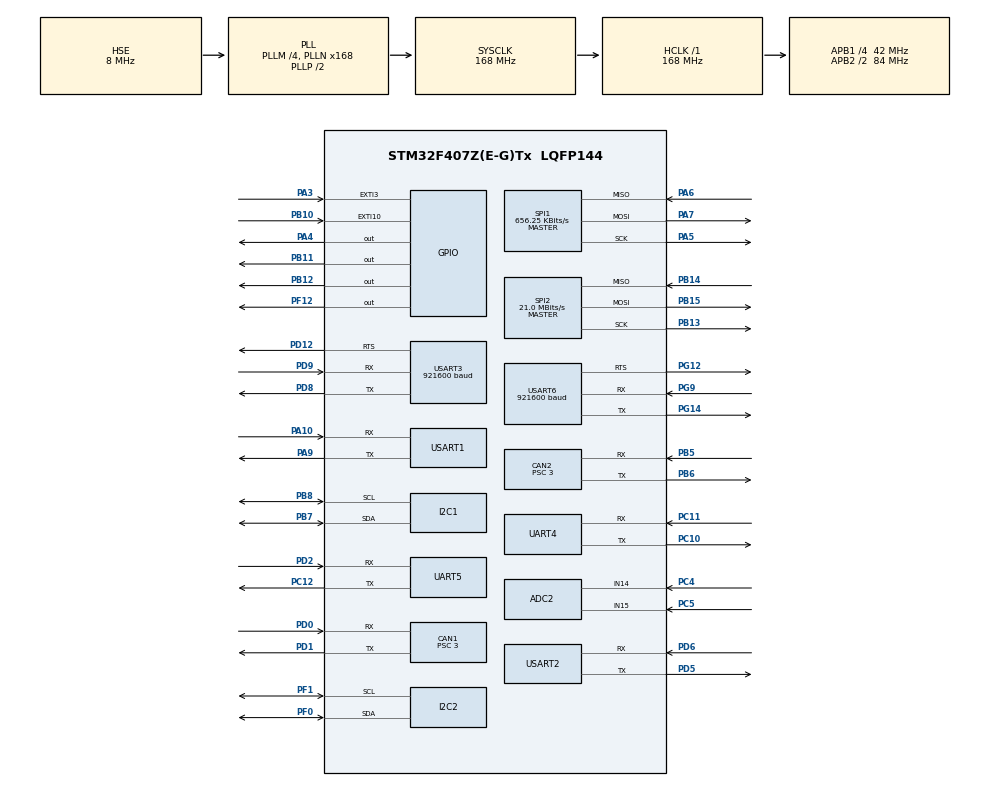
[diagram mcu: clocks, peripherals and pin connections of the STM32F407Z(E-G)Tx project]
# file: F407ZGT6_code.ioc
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ADC2.Channel-3\#ChannelRegularConversion=ADC_CHANNEL_14
ADC2.NbrOfConversionFlag=1
ADC2.Rank-3\#ChannelRegularConversion=1
ADC2.SamplingTime-3\#ChannelRegularConversion=ADC_SAMPLETIME_3CYCLES
CAN1.BS1=CAN_BS1_9TQ
CAN1.BS2=CAN_BS2_4TQ
CAN1.CalculateBaudRate=1000000
CAN1.CalculateTimeBit=1000
CAN1.CalculateTimeQuantum=71.42857142857143
CAN1.NART=ENABLE
CAN1.Prescaler=3
CAN2.BS1=CAN_BS1_9TQ
CAN2.BS2=CAN_BS2_4TQ
CAN2.CalculateBaudRate=1000000
CAN2.CalculateTimeBit=1000
CAN2.CalculateTimeQuantum=71.42857142857143
CAN2.NART=ENABLE
CAN2.Prescaler=3
Dma.Request0=UART4_TX
Dma.Request1=UART4_RX
Dma.Request2=UART5_RX
Dma.UART4_RX.1.Direction=DMA_PERIPH_TO_MEMORY
Dma.UART4_RX.1.FIFOMode=DMA_FIFOMODE_DISABLE
Dma.UART4_RX.1.Instance=DMA1_Stream2
Dma.UART4_RX.1.MemDataAlignment=DMA_MDATAALIGN_BYTE
Dma.UART4_RX.1.MemInc=DMA_MINC_ENABLE
Dma.UART4_RX.1.Mode=DMA_NORMAL
Dma.UART4_RX.1.PeriphDataAlignment=DMA_PDATAALIGN_BYTE
Dma.UART4_RX.1.PeriphInc=DMA_PINC_DISABLE
Dma.UART4_RX.1.Priority=DMA_PRIORITY_LOW
Dma.UART4_TX.0.Direction=DMA_MEMORY_TO_PERIPH
Dma.UART4_TX.0.FIFOMode=DMA_FIFOMODE_DISABLE
Dma.UART4_TX.0.Instance=DMA1_Stream4
Dma.UART4_TX.0.MemDataAlignment=DMA_MDATAALIGN_BYTE
Dma.UART4_TX.0.MemInc=DMA_MINC_ENABLE
Dma.UART4_TX.0.Mode=DMA_NORMAL
Dma.UART4_TX.0.PeriphDataAlignment=DMA_PDATAALIGN_BYTE
Dma.UART4_TX.0.PeriphInc=DMA_PINC_DISABLE
Dma.UART4_TX.0.Priority=DMA_PRIORITY_LOW
Dma.UART5_RX.2.Direction=DMA_PERIPH_TO_MEMORY
Dma.UART5_RX.2.FIFOMode=DMA_FIFOMODE_DISABLE
Dma.UART5_RX.2.Instance=DMA1_Stream0
Dma.UART5_RX.2.MemDataAlignment=DMA_MDATAALIGN_BYTE
Dma.UART5_RX.2.MemInc=DMA_MINC_ENABLE
Dma.UART5_RX.2.Mode=DMA_NORMAL
Dma.UART5_RX.2.PeriphDataAlignment=DMA_PDATAALIGN_BYTE
Dma.UART5_RX.2.PeriphInc=DMA_PINC_DISABLE
Dma.UART5_RX.2.Priority=DMA_PRIORITY_LOW
Mcu.Family=STM32F4
Mcu.Name=STM32F407Z(E-G)Tx
Mcu.Package=LQFP144
NVIC.CAN1_RX0_IRQn=true\:0\:0\:false\:false\:true\:true\:true\:true
NVIC.CAN2_RX0_IRQn=true\:0\:0\:false\:false\:true\:true\:true\:true
NVIC.DMA1_Stream0_IRQn=true\:0\:0\:false\:false\:true\:false\:true\:true
NVIC.DMA1_Stream2_IRQn=true\:0\:0\:false\:false\:true\:false\:true\:true
NVIC.DMA1_Stream4_IRQn=true\:0\:0\:false\:false\:true\:false\:true\:true
NVIC.EXTI15_10_IRQn=true\:0\:0\:false\:false\:true\:true\:true\:true
NVIC.EXTI3_IRQn=true\:0\:0\:false\:false\:true\:true\:true\:true
NVIC.PriorityGroup=NVIC_PRIORITYGROUP_4
NVIC.SPI1_IRQn=true\:0\:0\:false\:false\:true\:true\:true\:true
NVIC.TIM3_IRQn=true\:0\:0\:false\:false\:true\:true\:true\:true
NVIC.UART4_IRQn=true\:0\:0\:false\:false\:true\:true\:true\:true
NVIC.UART5_IRQn=true\:0\:0\:false\:false\:true\:true\:true\:true
NVIC.USART1_IRQn=true\:0\:0\:false\:false\:true\:true\:true\:true
PA10.Mode=Asynchronous
PA10.Signal=USART1_RX
PA13.Mode=Serial_Wire
PA13.Signal=SYS_JTMS-SWDIO
PA14.Mode=Serial_Wire
PA14.Signal=SYS_JTCK-SWCLK
PA3.GPIO_ModeDefaultEXTI=GPIO_MODE_IT_RISING
PA3.GPIO_PuPd=GPIO_PULLDOWN
PA3.Signal=GPXTI3
PA4.GPIO_Speed=GPIO_SPEED_FREQ_HIGH
PA4.PinState=GPIO_PIN_SET
PA4.Signal=GPIO_Output
PA5.GPIO_PuPd=GPIO_PULLUP
PA5.Mode=Full_Duplex_Master
PA5.Signal=SPI1_SCK
PA6.Mode=Full_Duplex_Master
PA6.Signal=SPI1_MISO
PA7.Mode=Full_Duplex_Master
PA7.Signal=SPI1_MOSI
PA9.Mode=Asynchronous
PA9.Signal=USART1_TX
PB10.GPIO_PuPd=GPIO_PULLDOWN
PB10.Signal=GPXTI10
PB11.Signal=GPIO_Output
PB12.Signal=GPIO_Output
PB13.Mode=Full_Duplex_Master
PB13.Signal=SPI2_SCK
PB14.Mode=Full_Duplex_Master
PB14.Signal=SPI2_MISO
PB15.Mode=Full_Duplex_Master
PB15.Signal=SPI2_MOSI
PB5.Mode=CAN_Activate
PB5.Signal=CAN2_RX
PB6.Mode=CAN_Activate
PB6.Signal=CAN2_TX
PB7.Mode=I2C
PB7.Signal=I2C1_SDA
PB8.Mode=I2C
PB8.Signal=I2C1_SCL
PC10.Mode=Asynchronous
PC10.Signal=UART4_TX
PC11.Mode=Asynchronous
PC11.Signal=UART4_RX
PC12.Mode=Asynchronous
PC12.Signal=UART5_TX
PC14-OSC32_IN.Mode=LSE-External-Oscillator
PC14-OSC32_IN.Signal=RCC_OSC32_IN
PC15-OSC32_OUT.Mode=LSE-External-Oscillator
PC15-OSC32_OUT.Signal=RCC_OSC32_OUT
PC4.Signal=ADCx_IN14
PC5.Signal=ADCx_IN15
PD0.Mode=CAN_Activate
PD0.Signal=CAN1_RX
PD1.Mode=CAN_Activate
PD1.Signal=CAN1_TX
PD12.Mode=RTS_Only
PD12.Signal=USART3_RTS
PD2.Mode=Asynchronous
PD2.Signal=UART5_RX
PD5.Mode=Asynchronous
PD5.Signal=USART2_TX
PD6.Mode=Asynchronous
PD6.Signal=USART2_RX
PD8.Mode=Asynchronous
PD8.Signal=USART3_TX
PD9.Mode=Asynchronous
PD9.Signal=USART3_RX
PF0.Mode=I2C
PF0.Signal=I2C2_SDA
PF1.Mode=I2C
PF1.Signal=I2C2_SCL
PF12.Signal=GPIO_Output
PG12.Mode=RTS_Only
PG12.Signal=USART6_RTS
PG14.Mode=Asynchronous
PG14.Signal=USART6_TX
PG9.Mode=Asynchronous
PG9.Signal=USART6_RX
PH0-OSC_IN.Mode=HSE-External-Oscillator
PH0-OSC_IN.Signal=RCC_OSC_IN
PH1-OSC_OUT.Mode=HSE-External-Oscillator
PH1-OSC_OUT.Signal=RCC_OSC_OUT
ProjectManager.HeapSize=0x200
ProjectManager.StackSize=0x400
ProjectManager.TargetToolchain=STM32CubeIDE
RCC.48MHZClocksFreq_Value=84000000
RCC.AHBFreq_Value=168000000
RCC.APB1CLKDivider=RCC_HCLK_DIV4
RCC.APB1Freq_Value=42000000
RCC.APB1TimFreq_Value=84000000
RCC.APB2CLKDivider=RCC_HCLK_DIV2
RCC.APB2Freq_Value=84000000
RCC.APB2TimFreq_Value=168000000
RCC.CortexFreq_Value=168000000
RCC.HCLKFreq_Value=168000000
RCC.HSE_VALUE=8000000
RCC.HSI_VALUE=16000000
RCC.PLLM=4
RCC.PLLN=168
RCC.PLLSourceVirtual=RCC_PLLSOURCE_HSE
RCC.SYSCLKFreq_VALUE=168000000
RCC.SYSCLKSource=RCC_SYSCLKSOURCE_PLLCLK
RCC.VCOOutputFreq_Value=336000000
SH.ADCx_IN14.0=ADC2_IN14,IN14
SH.ADCx_IN15.0=ADC2_IN15,IN15
SPI1.BaudRatePrescaler=SPI_BAUDRATEPRESCALER_128
SPI1.CLKPhase=SPI_PHASE_2EDGE
SPI1.CLKPolarity=SPI_POLARITY_HIGH
SPI1.CalculateBaudRate=656.25 KBits/s
SPI1.Direction=SPI_DIRECTION_2LINES
SPI1.Mode=SPI_MODE_MASTER
SPI1.VirtualType=VM_MASTER
SPI2.BaudRatePrescaler=SPI_BAUDRATEPRESCALER_2
SPI2.CalculateBaudRate=21.0 MBits/s
SPI2.Direction=SPI_DIRECTION_2LINES
SPI2.Mode=SPI_MODE_MASTER
SPI2.VirtualType=VM_MASTER
STMicroelectronics.X-CUBE-ALGOBUILD.1.4.0.LibraryCcDSPOoLibraryJjDSPOoLibrary=true
TIM3.Period=1999
TIM3.Prescaler=839
UART4.Parity=PARITY_NONE
UART4.VirtualMode=Asynchronous
UART4.WordLength=WORDLENGTH_8B
UART5.VirtualMode=Asynchronous
USART1.VirtualMode=VM_ASYNC
USART2.VirtualMode=VM_ASYNC
USART3.BaudRate=921600
USART3.VirtualMode=VM_ASYNC
USART6.BaudRate=921600
USART6.StopBits=STOPBITS_1
USART6.VirtualMode=VM_ASYNC
VP_STMicroelectronics.X-CUBE-ALGOBUILD_VS_DSPOoLibraryJjLibrary_1.4.0_1.4.0.Mode=DSPOoLibraryJjLibrary
VP_TIM3_VS_ClockSourceINT.Mode=Internal
board=custom

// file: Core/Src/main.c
/* USER CODE BEGIN Header */
/**
 ******************************************************************************
 * @file           : main.c
 * @brief          : Main program body
 ******************************************************************************
 * @attention
 *
 * Copyright (c) 2025 STMicroelectronics.
 * All rights reserved.
 *
 * This software is licensed under terms that can be found in the LICENSE file
 * in the root directory of this software component.
 * If no LICENSE file comes with this software, it is provided AS-IS.
 *
 ******************************************************************************
 */
/* USER CODE END Header */
#include "main.h"
#include "adc.h"
#include "can.h"
#include "dma.h"
#include "i2c.h"
#include "spi.h"
#include "tim.h"
#include "usart.h"
#include "gpio.h"

/* USER CODE BEGIN Includes */

//#include "test.h"
#include <stdio.h>

#include "../user/joint_motor/comm_can.h"
#include "../user/sys/app.h"
//#include "../user/sys/misc.h.txt"
//#include "../User/Comm/not_use/comm_rs485.h.1"

/* USER CODE END Includes */

void SystemClock_Config(void);
/* USER CODE BEGIN PFP */

int _write(int file, char *ptr, int len);

/* USER CODE END PFP */

int main(void)
{

  /* USER CODE BEGIN 1 */
	/**
	 * 需要做的事：
	 * 1、测试主控是否能接收到关节电机can通信返回的数据（已实现！）
	 * 2、写一个中间层，介于应用层的代码与关节电机控制函数之间，可以被应用层调用，转换后传给控制函数
	 * 3、加一个定时器，周期20ms（50Hz），作为运动控制环，控制关节电机和轮毂电机（已实现！）
	 * 4、完善FOC驱动器的代码，增加与主控的通信（几乎已实现！）
	 * 5、增加上电后的无传感器回零功能，其中，LF和RF关节电机下摆直至撞到碳板（此时与原点成
	 * 确定的角度），LR和RR关节电机增加限位块。基本步骤：（已实现！）
	 * （1）设置速度模式的力矩为一个较小但要够用的值（保证可以撞到限位但不会造成损坏）
	 * （2）设置为速度模式，给一个不用很大的速度，缓慢移动，撞到限位
	 * （3）在第二步的同时，不停地读取力矩，当力矩达到设定值（允许有一定的偏差）时，认为撞到了限位
	 * （4）相对位置控制，旋转一定角度（需要提前测算好），使得大腿竖直下垂
	 * ！！！需询问伺泰威的工程师，相对位置控制以及设置当前位置为原点，是按照当前的机械角度（实际角度）
	 * 还是目标角度？重要！！！（已询问待回复）
	 * （5）设置当前位置（大腿竖直下垂）为原点
	 * 6、尽早实现逆运动学
	 * 7、尽早实现轮足机器人动力学
	 * 8、尽早实现读取IMU（已实现）
	 */
  /* USER CODE END 1 */

  /* MCU Configuration--------------------------------------------------------*/

  /* Reset of all peripherals, Initializes the Flash interface and the Systick. */
  HAL_Init();

  /* Configure the system clock */
  SystemClock_Config();

  /* Initialize all configured peripherals */
  MX_GPIO_Init();
  MX_DMA_Init();
  MX_USART3_UART_Init();
  MX_USART6_UART_Init();
  MX_CAN1_Init();
  MX_CAN2_Init();
  MX_I2C1_Init();
  MX_SPI1_Init();
  MX_SPI2_Init();
  MX_I2C2_Init();
  MX_UART4_Init();
  MX_USART1_UART_Init();
  MX_USART2_UART_Init();
  MX_UART5_Init();
  MX_ADC2_Init();
  MX_TIM3_Init();
  /* USER CODE BEGIN 2 */
	appSetup();

  /* USER CODE END 2 */

  /* Infinite loop */
  /* USER CODE BEGIN WHILE */
	while (1) {
		/*
		 HAL_Delay(1000);
		 CommCan_SetAbsPosition_Count(&hcan1, idLF, 0);
		 CommCan_SetAbsPosition_Count(&hcan1, idLR, 0);
		 CommCan_SetAbsPosition_Count(&hcan2, idRF, 0);
		 CommCan_SetAbsPosition_Count(&hcan2, idRR, 0);
		 HAL_Delay(1000);
		 CommCan_SetAbsPosition_Count(&hcan1, idLF, 1024);
		 CommCan_SetAbsPosition_Count(&hcan1, idLR, 1024);
		 CommCan_SetAbsPosition_Count(&hcan2, idRF, 1024);
		 CommCan_SetAbsPosition_Count(&hcan2, idRR, 1024);
		 //printf("a cycle\n");
		 */
		appLoop();
    /* USER CODE END WHILE */

	}
}

void SystemClock_Config(void)
{
  RCC_OscInitTypeDef RCC_OscInitStruct = {0};
  RCC_ClkInitTypeDef RCC_ClkInitStruct = {0};

  /** Configure the main internal regulator output voltage
  */
  __HAL_RCC_PWR_CLK_ENABLE();
  __HAL_PWR_VOLTAGESCALING_CONFIG(PWR_REGULATOR_VOLTAGE_SCALE1);

  /** Initializes the RCC Oscillators according to the specified parameters
  * in the RCC_OscInitTypeDef structure.
  */
  RCC_OscInitStruct.OscillatorType = RCC_OSCILLATORTYPE_HSE;
  RCC_OscInitStruct.HSEState = RCC_HSE_ON;
  RCC_OscInitStruct.PLL.PLLState = RCC_PLL_ON;
  RCC_OscInitStruct.PLL.PLLSource = RCC_PLLSOURCE_HSE;
  RCC_OscInitStruct.PLL.PLLM = 4;
  RCC_OscInitStruct.PLL.PLLN = 168;
  RCC_OscInitStruct.PLL.PLLP = RCC_PLLP_DIV2;
  RCC_OscInitStruct.PLL.PLLQ = 4;
  if (HAL_RCC_OscConfig(&RCC_OscInitStruct) != HAL_OK)
  {
    Error_Handler();
  }

  /** Initializes the CPU, AHB and APB buses clocks
  */
  RCC_ClkInitStruct.ClockType = RCC_CLOCKTYPE_HCLK|RCC_CLOCKTYPE_SYSCLK
                              |RCC_CLOCKTYPE_PCLK1|RCC_CLOCKTYPE_PCLK2;
  RCC_ClkInitStruct.SYSCLKSource = RCC_SYSCLKSOURCE_PLLCLK;
  RCC_ClkInitStruct.AHBCLKDivider = RCC_SYSCLK_DIV1;
  RCC_ClkInitStruct.APB1CLKDivider = RCC_HCLK_DIV4;
  RCC_ClkInitStruct.APB2CLKDivider = RCC_HCLK_DIV2;

  if (HAL_RCC_ClockConfig(&RCC_ClkInitStruct, FLASH_LATENCY_5) != HAL_OK)
  {
    Error_Handler();
  }
}

/* USER CODE BEGIN 4 */

int _write(int file, char *ptr, int len) {
	HAL_UART_Transmit(&huart1, (uint8_t*) ptr, len, HAL_MAX_DELAY);
	return len;
}

/* USER CODE END 4 */

void Error_Handler(void)
{
	__disable_irq();
	while (1) {
	}
}
